# input register map
Registers are access not given, reset 0x0 unless marked. A register's access mark holds for its fields unless they carry their own. Offsets are from the block's base; lines under a group give offsets from that group; [hi:lo] are bit positions; {n}, {i} and the like mark numbered series; 'fields as' and 'values as' point back to an identical list; <NAME> marks a mode.

## Memory map
0x40013000 SPI1 — Serial Peripheral Interface 1

## SPI1 — Serial Peripheral Interface 1
Base 0x40013000
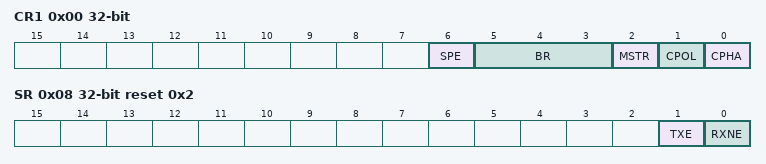
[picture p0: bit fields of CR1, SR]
0x00 CR1 — Control Register 1
  [6] SPE — SPI Enable
  [5:3] BR — Baud Rate Control
  [2] MSTR — Master Selection
  [1] CPOL — Clock Polarity
  [0] CPHA — Clock Phase
0x08 SR reset 0x2 — Status Register
  [1] TXE — Transmit Buffer Empty
  [0] RXNE — Receive Buffer Not Empty
0x0C DR — Data Register
